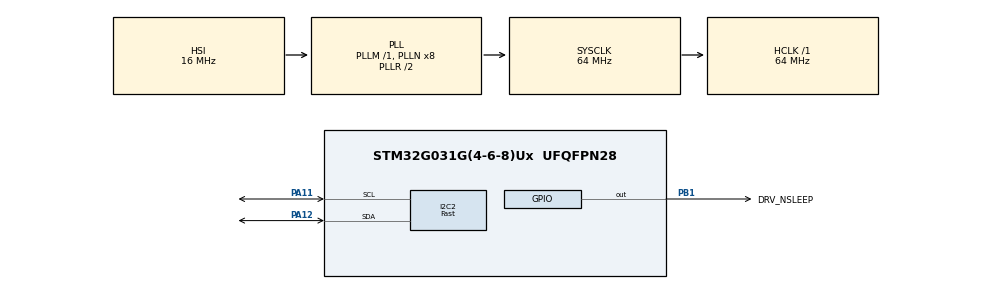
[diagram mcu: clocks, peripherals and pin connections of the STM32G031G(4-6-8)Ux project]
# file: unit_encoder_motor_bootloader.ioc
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CRC.DefaultInitValueUse=DEFAULT_INIT_VALUE_DISABLE
CRC.InitValue=0xffffffff
CRC.InputDataInversionMode=CRC_INPUTDATA_INVERSION_BYTE
CRC.OutputDataInversionMode=CRC_OUTPUTDATA_INVERSION_ENABLE
I2C2.I2C_Speed_Mode=I2C_Fast
I2C2.OwnAddress=0x54 << 1
I2C2.Timing=0x00C12166
Mcu.Family=STM32G0
Mcu.Name=STM32G031G(4-6-8)Ux
Mcu.Package=UFQFPN28
NVIC.I2C2_IRQn=true\:1\:0\:true\:false\:true\:true\:true\:true
PA11\ [PA9].GPIO_Pu=GPIO_PULLUP
PA11\ [PA9].Mode=I2C
PA11\ [PA9].Signal=I2C2_SCL
PA12\ [PA10].GPIO_Pu=GPIO_PULLUP
PA12\ [PA10].Mode=I2C
PA12\ [PA10].Signal=I2C2_SDA
PB1.GPIO_Label=DRV_NSLEEP
PB1.PinState=GPIO_PIN_RESET
PB1.Signal=GPIO_Output
ProjectManager.HeapSize=0x200
ProjectManager.StackSize=0x400
ProjectManager.TargetToolchain=STM32CubeIDE
RCC.ADCFreq_Value=64000000
RCC.AHBFreq_Value=64000000
RCC.CortexFreq_Value=64000000
RCC.EXTERNAL_CLOCK_VALUE=12288000
RCC.HCLKFreq_Value=64000000
RCC.HSE_VALUE=8000000
RCC.HSI_VALUE=16000000
RCC.LSE_VALUE=32768
RCC.SYSCLKFreq_VALUE=64000000
RCC.SYSCLKSource=RCC_SYSCLKSOURCE_PLLCLK
RCC.VCOOutputFreq_Value=128000000
VP_CRC_VS_CRC.Mode=CRC_Activate
board=custom

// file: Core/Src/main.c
/* USER CODE BEGIN Header */
/**
 ******************************************************************************
 * @file           : main.c
 * @brief          : Main program body
 ******************************************************************************
 * @attention
 *
 * Copyright (c) 2025 STMicroelectronics.
 * All rights reserved.
 *
 * This software is licensed under terms that can be found in the LICENSE file
 * in the root directory of this software component.
 * If no LICENSE file comes with this software, it is provided AS-IS.
 *
 ******************************************************************************
 */
/* USER CODE END Header */
#include "main.h"
#include "crc.h"
#include "i2c.h"
#include "gpio.h"

/* USER CODE BEGIN Includes */
#include "stm32g0xx_hal_flash_ex.h"
/* USER CODE END Includes */

/* USER CODE BEGIN PTD */
typedef enum {
    NOEVENT                  = 0,  // not enevt happen
    EVENT_OPCOD_NOTYET_READ  = 1,  // operation code not been read
    EVENT_OPCOD_READ         = 2,  // operation code has been readed
    EVENT_OPCOD_SEND         = 3,  // Feedback the status of MCU
    EVENT_OPCOD_BUSY_RECEIVE = 4   // I2C is in Busy of receive status
    // EVENT_OPCOD_BUSY_SEND =5 //i2C is busy of send
} EventStatus;
/* USER CODE END PTD */

/* USER CODE BEGIN PD */
typedef void (*pFunction)(void);
/*this address is define */
#define APPLICATION_ADDRESS 0x08002800
#define FW_LENGTH           (((uint32_t)0xF800) - ((uint32_t)0x2800))
#define FW_CRC_ADDR         (((uint32_t)0x0800F800) - ((uint32_t)4))

/* Error codes used to make the red led blinking */
#define ERROR_ERASE              0x01
#define ERROR_PROG               0x02
#define ERROR_HALF_PROG          0x04
#define ERROR_PROG_FLAG          0x08
#define ERROR_WRITE_PROTECTION   0x10
#define ERROR_FETCH_DURING_ERASE 0x20
#define ERROR_FETCH_DURING_PROG  0x40
#define ERROR_SIZE               0x80
#define ERROR_ALIGNMENT          0x100
#define ERROR_NOT_ZERO           0x200
#define ERROR_UNKNOWN            0x400
#define ERROR_I2C                0x01
#define ERROR_HSI_TIMEOUT        0x55
#define ERROR_PLL_TIMEOUT        0xAA
#define ERROR_CLKSWITCH_TIMEOUT  0xBB

#define DELAY_TIME     500
#define LED_FLASH_TIME 200

#define OPC_WREN  (uint8_t)(0x06)
#define OPC_USRCD (uint8_t)(0x77)

#define I2C_MAX_NUMS 2056

#define STM32G0xx_PAGE_SIZE             0x800
#define STM32G0xx_FLASH_PAGE0_STARTADDR 0x8000000
/* USER CODE END PD */

/* USER CODE BEGIN PV */
volatile uint32_t lastTime = 0;

volatile uint16_t I2C_Receive_Counter         = 0;
volatile uint8_t Receive_Buffer[I2C_MAX_NUMS] = {0};
volatile EventStatus i2c_event                = NOEVENT;
volatile uint16_t error                       = 0;
volatile uint32_t NbrOfPage                   = 0x00;
volatile uint32_t EraseCounter = 0x00, Address = 0x00;
volatile uint32_t JumpAddress = 0;
volatile pFunction JumpToApplication;
volatile uint8_t opcode = 0;

volatile uint8_t gpio_init_flag            = 0;
volatile uint32_t bootloader_led_delay     = 0;
volatile uint8_t bootloader_flash_led_flag = 0;
/* USER CODE END PV */

void SystemClock_Config(void);
/* USER CODE BEGIN PFP */
static uint8_t iwdg_is_enabled(void);
/* USER CODE END PFP */

/* USER CODE BEGIN 0 */
static void i2c2_it_disable(void)
{
    LL_I2C_DisableIT_ADDR(I2C2);
    LL_I2C_DisableIT_TX(I2C2);
    LL_I2C_DisableIT_RX(I2C2);
    LL_I2C_DisableIT_NACK(I2C2);
    LL_I2C_DisableIT_ERR(I2C2);
    LL_I2C_DisableIT_STOP(I2C2);
}

static void i2c2_it_enable(void)
{
    LL_I2C_Enable(I2C2);

    /* (6) Enable I2C2 address match/error interrupts:
     *  - Enable Address Match Interrupt
     *  - Enable Not acknowledge received interrupt
     *  - Enable Error interrupts
     *  - Enable Stop interrupt
     */
    LL_I2C_EnableIT_ADDR(I2C2);
    LL_I2C_EnableIT_NACK(I2C2);
    LL_I2C_EnableIT_ERR(I2C2);
    LL_I2C_EnableIT_STOP(I2C2);
}

static void i2c2_reset(void)
{
    LL_I2C_DeInit(I2C2);
    LL_I2C_Disable(I2C2);
    i2c2_it_disable();
    MX_I2C2_Init();
    i2c2_it_enable();
}

uint8_t compute_fw_crc32(void)
{
    uint32_t crcsum, crc_read, len;
    uint8_t *pdata = (uint8_t *)APPLICATION_ADDRESS;

    len      = FW_LENGTH - 4;
    crc_read = *(uint32_t *)FW_CRC_ADDR;

    crcsum = HAL_CRC_Calculate(&hcrc, (uint32_t *)pdata, len) ^ 0xffffffff;

    if (crc_read == crcsum)
        return 1;
    else
        return 0;
}

/**
 * @brief  Gets the page of a given address
 * @param  Addr: Address of the FLASH Memory
 * @retval The page of a given address
 */
static uint32_t GetPage(uint32_t Addr)
{
    return (Addr - STM32G0xx_FLASH_PAGE0_STARTADDR) / FLASH_PAGE_SIZE;
}

/**
 * Brief   This function handles I2C2 interrupt request.
 * Param   None
 * Retval  I2C2 always as slave of i2c conmunication
 */
void I2C2_IRQHandler(void)
{
    uint32_t I2C_InterruptStatus = I2C2->ISR; /* Get interrupt status */

    if ((I2C_InterruptStatus & I2C_ISR_ADDR) == I2C_ISR_ADDR) /* Check address match */
    {
        I2C2->ICR |= I2C_ICR_ADDRCF; /* Clear address match flag*/

        if ((I2C2->ISR & I2C_ISR_DIR) == I2C_ISR_DIR) /* Check if transfer direction is read (slave transmitter) */
        {
            I2C2->CR1 |= I2C_CR1_TXIE;    /* Set transmit IT /status*/
            i2c_event = EVENT_OPCOD_SEND; /* Set I2C  entor transmit mode*/

        } else /*Write operation, slave receive status*/
        {
            I2C2->CR1 |= I2C_CR1_RXIE;            /* Set receive IT /status*/
            i2c_event = EVENT_OPCOD_BUSY_RECEIVE; /* Set I2C  entor receive mode*/
        }

        LL_I2C_EnableIT_ERR(I2C2);    // Enable ERR interrupt
        I2C2->CR1 |= I2C_CR1_STOPIE;  // Enable STOP interrupt

    } else if ((I2C_InterruptStatus & I2C_ISR_TXIS) == I2C_ISR_TXIS) {
        LL_I2C_TransmitData8(I2C2, 1);
        // add some application code in this place
    }
    /*check RXDR is not empty*/
    else if ((I2C_InterruptStatus & I2C_ISR_RXNE) == I2C_ISR_RXNE) {
        if (I2C_Receive_Counter >= I2C_MAX_NUMS) {
            I2C_Receive_Counter = 0;
        }
        // I2C_ISR_RXNE add you code in this place Tomas Li add
        Receive_Buffer[I2C_Receive_Counter] = I2C2->RXDR;
        I2C_Receive_Counter++;
        i2c_event = EVENT_OPCOD_BUSY_RECEIVE;  // slave is busy for receive data

    } else if (LL_I2C_IsActiveFlag_NACK(I2C2)) {
        /* End of Transfer */
        LL_I2C_ClearFlag_NACK(I2C2);
    }
    /*check Stop event happen */
    if ((I2C_InterruptStatus & I2C_ISR_STOPF) == I2C_ISR_STOPF) {
        I2C2->ICR |= I2C_ICR_STOPCF;  // clear the STOP interrupt Flag

#if 1
        switch (i2c_event) {
            case EVENT_OPCOD_BUSY_RECEIVE:  // slave receive status Stop flag
                I2C_Receive_Counter = 0;
                i2c_event           = EVENT_OPCOD_NOTYET_READ;

                I2C2->CR1 &= ~(I2C_CR1_STOPIE);  // Disable all interrupt.except Error interrupt
                I2C2->CR2 |= I2C_CR2_NACK;       // set feedback Nack in next event
                I2C2->CR1 |= I2C_CR1_ADDRIE;
                break;
            case EVENT_OPCOD_SEND:                                              // slave send stop
                I2C2->ICR |= I2C_ICR_STOPCF | I2C_ICR_NACKCF | I2C_ICR_BERRCF;  // clear the STOP interrupt Flag
                I2C2->CR1 |= I2C_CR1_ADDRIE;
                i2c_event = NOEVENT;

                break;
            default:

                break;
        }
#endif

    } else {
        error = ERROR_I2C; /* Report an error */
    }
    if (LL_I2C_IsActiveFlag_BERR(I2C2)) {
        LL_I2C_ClearFlag_BERR(I2C2);
        i2c2_reset();
    }
    if (LL_I2C_IsActiveFlag_ARLO(I2C2)) {
        LL_I2C_ClearFlag_ARLO(I2C2);
        i2c2_reset();
    }
}

uint8_t Reset_AllPeriph(void)
{
    uint8_t status = HAL_ERROR;

    // disable i2c
    LL_I2C_DeInit(I2C2);
    LL_I2C_DisableAutoEndMode(I2C2);
    LL_I2C_Disable(I2C2);
    LL_I2C_DisableIT_ADDR(I2C2);

    SysTick->CTRL = 0;
    SYSCFG->CFGR1 &= SYSCFG_CFGR1_MEM_MODE;
    NVIC->ICER[0] = 0xFFFFFFFF;
    NVIC->ICPR[0] = 0xFFFFFFFF;
    /* Set EXTICRx registers to reset value */
    EXTI->EXTICR[0] = 0;
    EXTI->EXTICR[1] = 0;
    EXTI->EXTICR[2] = 0;
    EXTI->EXTICR[3] = 0;
    /* Set CFGR2 register to reset value: clear SRAM parity error flag */
    SYSCFG->CFGR2 |= (uint32_t)SYSCFG_CFGR2_SRAM_PE;
    // set clock to default
    status = HAL_RCC_DeInit();
    __HAL_SYSCFG_CLEAR_FLAG();
    status |= HAL_CRC_DeInit(&hcrc);
    // HAL_DeInit();
    SysTick->CTRL = 0;
    SysTick->LOAD = 0;
    SysTick->VAL  = 0;

    return status;
}

void Jump_APP(void)
{
    uint32_t jump_app_timeout = 0;

    if (compute_fw_crc32()) {
        /*check the application address context whether avilible*/
        if (((*(__IO uint32_t *)APPLICATION_ADDRESS) & 0x2FFE0000) == 0x20000000) {
            while (Reset_AllPeriph() != HAL_OK) {
                jump_app_timeout++;
                if (jump_app_timeout > 20) {
                    jump_app_timeout = 0;
                    HAL_NVIC_SystemReset();
                    HAL_Delay(1000);
                }
            }

            SCB->VTOR = APPLICATION_ADDRESS;
            /* Jump to user application */
            JumpAddress       = *(__IO uint32_t *)(APPLICATION_ADDRESS + 4);
            JumpToApplication = (pFunction)JumpAddress;
            /* Initialize user application's Stack Pointer */
            __set_MSP(*(__IO uint32_t *)APPLICATION_ADDRESS);
            JumpToApplication();
        }
    }
}

void Write_Code(void)
{
    uint16_t Number_Bytes_Transferred = 0;
    uint32_t Add_Flash, end_add_flash;
    uint64_t Data       = 0;
    uint16_t Data_index = 8;
    uint32_t PageError  = 0;  // 设置PageError,如果出现错误这个变量会被设置为出错的FLASH地址
    FLASH_EraseInitTypeDef My_Flash;
    uint32_t PageNum     = 0;
    uint32_t opt_timeout = 0;

    Add_Flash     = Receive_Buffer[1] << 24 | Receive_Buffer[2] << 16 | Receive_Buffer[3] << 8 | Receive_Buffer[4] << 0;
    end_add_flash = Add_Flash + 2048;

    // return if address illegal
    if (Add_Flash < APPLICATION_ADDRESS) {
        return;
    }

    Number_Bytes_Transferred = (Receive_Buffer[5] << 8) + Receive_Buffer[6];

    if (Number_Bytes_Transferred > 0) {
        if (__HAL_FLASH_GET_FLAG(FLASH_FLAG_CFGBSY) != 0x00U) {
            *(uint32_t *)(Add_Flash + 600) = 12323;
            FLASH->SR                      = FLASH_SR_CLEAR;
        }
    step_unlock:
        if (iwdg_is_enabled()) IWDG->KR = 0xAAAA;  // 喂狗
        if (HAL_FLASH_Unlock() != HAL_OK) {
            opt_timeout++;
            if (opt_timeout > 100) {
                HAL_FLASH_Lock();
                HAL_NVIC_SystemReset();
            }
            goto step_unlock;
        }

        PageNum = GetPage(Add_Flash);

        My_Flash.TypeErase = FLASH_TYPEERASE_PAGES;  // 标明Flash执行页面只做擦除操作
        My_Flash.Page      = PageNum;
        My_Flash.NbPages =
            1;  // 说明要擦除的页数，此参数必须是Min_Data = 1和Max_Data =(�????大页�????-初始页的�????)之间的�??

        opt_timeout = 0;
    step_erase:
        if (iwdg_is_enabled()) IWDG->KR = 0xAAAA;  // 喂狗
        FLASH_WaitForLastOperation(50);
        if (HAL_FLASHEx_Erase(&My_Flash, &PageError) != HAL_OK) {
            opt_timeout++;
            if (opt_timeout > 100) {
                HAL_FLASH_Lock();
                HAL_NVIC_SystemReset();
            }
            goto step_erase;
        }  // 调用擦除函数擦除

        while (Add_Flash < end_add_flash) {
            Data = Receive_Buffer[Data_index] | ((uint64_t)Receive_Buffer[Data_index + 1] << 8) |
                   ((uint64_t)Receive_Buffer[Data_index + 2] << 16) | ((uint64_t)Receive_Buffer[Data_index + 3] << 24) |
                   ((uint64_t)Receive_Buffer[Data_index + 4] << 32) | ((uint64_t)Receive_Buffer[Data_index + 5] << 40) |
                   ((uint64_t)Receive_Buffer[Data_index + 6] << 48) | ((uint64_t)Receive_Buffer[Data_index + 7] << 56);

            opt_timeout = 0;
        step_write:
            if (iwdg_is_enabled()) IWDG->KR = 0xAAAA;  // 喂狗
            FLASH_WaitForLastOperation(50);
            if (HAL_FLASH_Program(FLASH_TYPEPROGRAM_DOUBLEWORD, Add_Flash, Data) != HAL_OK) {
                opt_timeout++;
                if (opt_timeout > 100) {
                    HAL_FLASH_Lock();
                    HAL_NVIC_SystemReset();
                }
                goto step_write;
            }
            Add_Flash  = Add_Flash + 8;
            Data_index = Data_index + 8;
        }
        if (HAL_FLASH_Lock() != HAL_OK) {
            HAL_NVIC_SystemReset();
        }
        FLASH_WaitForLastOperation(50);
    }
    for (int i = 0; i < sizeof(Receive_Buffer); i++) {
        Receive_Buffer[i] = 0;
    }
}

void iap_i2c(void)
{
    /*this is a endless loop for process the data from Host side*/
    while (1) {
        // Tomas_Li_Test();//Just for Test
        if (iwdg_is_enabled()) IWDG->KR = 0xAAAA;  // 喂狗

        if (HAL_GetTick() > lastTime) {
            Jump_APP();
        }

        if (i2c_event == EVENT_OPCOD_NOTYET_READ) {
            NVIC_DisableIRQ(I2C2_IRQn);
            i2c_event = NOEVENT;  // changed the status
            /* Read opcode */
            switch (Receive_Buffer[0]) {
                case OPC_WREN:
                    lastTime = HAL_GetTick() + DELAY_TIME * 1000;
                    Write_Code();
                    break;

                case OPC_USRCD:
                    Jump_APP();
                    break;

                default:
                    break;
            }
            NVIC_EnableIRQ(I2C2_IRQn);
            I2C2->CR1 |= I2C_CR1_ADDRIE;  // Open address and Stop interrupt
            LL_I2C_Enable(I2C2);
            LL_I2C_EnableIT_ADDR(I2C2);
        }
    }
}

static uint8_t iwdg_is_enabled(void)
{
    // 检查状态寄存器是否配置完成
    if ((IWDG->SR & 0x03) != 0) {  // PVU或RVU为1，配置未完成
        return 0;
    }

    // 检查预分频和重装载值是否非默认值
    if ((IWDG->PR == 0) && (IWDG->RLR == 0xFFF)) {
        return 0;  // 未配置过IWDG
    }
    return 1;
}

/**
 * @brief Initialize GPIO for IAP.
 * @note This function configures the GPIO pins for input with
 *       pull-up resistors, which are used for IAP operations.
 *
 * @param None
 * @retval None
 */
void iap_gpio_init(void)
{
    GPIO_InitTypeDef GPIO_InitStruct = {0};

    /* Enable the GPIO port clock */
    __HAL_RCC_GPIOA_CLK_ENABLE();

    /*Configure GPIO pin Output Level */
    HAL_GPIO_WritePin(GPIOA, GPIO_PIN_11, GPIO_PIN_RESET);

    /*Configure GPIO pin Output Level */
    HAL_GPIO_WritePin(GPIOA, GPIO_PIN_12, GPIO_PIN_RESET);

    /* Configure GPIO pins : PB6 and PB7 */
    GPIO_InitStruct.Pin   = GPIO_PIN_11 | GPIO_PIN_12;  // Configure pins PA11 and PA12
    GPIO_InitStruct.Mode  = GPIO_MODE_INPUT;            // Set mode to input
    GPIO_InitStruct.Pull  = GPIO_PULLUP;                // Enable pull-up mode
    GPIO_InitStruct.Speed = GPIO_SPEED_FREQ_LOW;
    HAL_GPIO_Init(GPIOA, &GPIO_InitStruct);  // Initialize GPIOB with the defined settings
}

/* USER CODE END 0 */

int main(void)
{

    /* MCU Configuration--------------------------------------------------------*/

    /* Reset of all peripherals, Initializes the Flash interface and the Systick. */
    HAL_Init();

    /* Configure the system clock */
    SystemClock_Config();

    /* Initialize all configured peripherals */
    MX_GPIO_Init();
    // MX_I2C2_Init();
    MX_CRC_Init();
    /* USER CODE BEGIN 2 */
    if (iwdg_is_enabled()) {
        IWDG->KR = 0xAAAA;  // 喂狗
    }
    __enable_irq();
    iap_gpio_init();
    HAL_Delay(30);
    if ((!(!!(GPIOA->IDR & GPIO_PIN_11))) && (!(!!(GPIOA->IDR & GPIO_PIN_12)))) {
        lastTime = HAL_GetTick() + DELAY_TIME;
    }
    MX_I2C2_Init();
    LL_I2C_Enable(I2C2);
    LL_I2C_EnableIT_ADDR(I2C2);
    iap_i2c();
    /* USER CODE END 2 */

    /* Infinite loop */
    while (1) {

    }
}

void SystemClock_Config(void)
{
    RCC_OscInitTypeDef RCC_OscInitStruct = {0};
    RCC_ClkInitTypeDef RCC_ClkInitStruct = {0};

    /** Configure the main internal regulator output voltage
     */
    HAL_PWREx_ControlVoltageScaling(PWR_REGULATOR_VOLTAGE_SCALE1);

    /** Initializes the RCC Oscillators according to the specified parameters
     * in the RCC_OscInitTypeDef structure.
     */
    RCC_OscInitStruct.OscillatorType      = RCC_OSCILLATORTYPE_HSI | RCC_OSCILLATORTYPE_LSI;
    RCC_OscInitStruct.HSIState            = RCC_HSI_ON;
    RCC_OscInitStruct.HSIDiv              = RCC_HSI_DIV1;
    RCC_OscInitStruct.HSICalibrationValue = RCC_HSICALIBRATION_DEFAULT;
    RCC_OscInitStruct.LSIState            = RCC_LSI_ON;
    RCC_OscInitStruct.PLL.PLLState        = RCC_PLL_ON;
    RCC_OscInitStruct.PLL.PLLSource       = RCC_PLLSOURCE_HSI;
    RCC_OscInitStruct.PLL.PLLM            = RCC_PLLM_DIV1;
    RCC_OscInitStruct.PLL.PLLN            = 8;
    RCC_OscInitStruct.PLL.PLLP            = RCC_PLLP_DIV2;
    RCC_OscInitStruct.PLL.PLLQ            = RCC_PLLQ_DIV2;
    RCC_OscInitStruct.PLL.PLLR            = RCC_PLLR_DIV2;
    if (HAL_RCC_OscConfig(&RCC_OscInitStruct) != HAL_OK) {
        Error_Handler();
    }

    /** Initializes the CPU, AHB and APB buses clocks
     */
    RCC_ClkInitStruct.ClockType      = RCC_CLOCKTYPE_HCLK | RCC_CLOCKTYPE_SYSCLK | RCC_CLOCKTYPE_PCLK1;
    RCC_ClkInitStruct.SYSCLKSource   = RCC_SYSCLKSOURCE_PLLCLK;
    RCC_ClkInitStruct.AHBCLKDivider  = RCC_SYSCLK_DIV1;
    RCC_ClkInitStruct.APB1CLKDivider = RCC_HCLK_DIV1;

    if (HAL_RCC_ClockConfig(&RCC_ClkInitStruct, FLASH_LATENCY_2) != HAL_OK) {
        Error_Handler();
    }
}

void Error_Handler(void)
{
    /* USER CODE BEGIN Error_Handler_Debug */
    /* User can add his own implementation to report the HAL error return state */
    __disable_irq();
    while (1) {
        HAL_NVIC_SystemReset();
    }
    /* USER CODE END Error_Handler_Debug */
}
